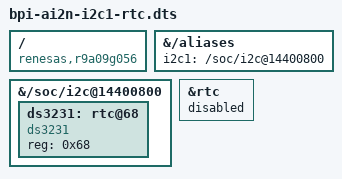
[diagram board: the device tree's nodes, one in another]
/dts-v1/;
/plugin/;

/ {
	compatible = "renesas,r9a09g056";

	fragment@0 {
		target-path = "/aliases";
		__overlay__ {
			i2c1 = "/soc/i2c@14400800";
		};
	};

	fragment@1 {
		target-path = "/soc/i2c@14400800";
		__overlay__ {
			status = "okay";

			ds3231: rtc@68 {
				status = "okay";
				compatible = "ds3231";
				reg = <0x68>;
			};
		};	
	};

	fragment@2 {
		target = <&rtc>;

		__overlay__ {
			status = "disabled";
		};
	};
};
